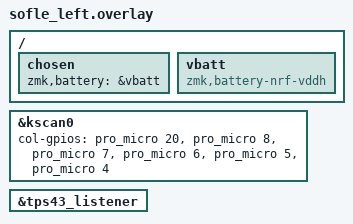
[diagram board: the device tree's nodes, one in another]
/*
 * Copyright (c) 2020 Ryan Cross
 *
 * SPDX-License-Identifier: MIT
 */
#include "sofle.dtsi"

&kscan0 {
    col-gpios
       = <&pro_micro 20 GPIO_ACTIVE_HIGH>
        , <&pro_micro 8 GPIO_ACTIVE_HIGH>
        , <&pro_micro 7 GPIO_ACTIVE_HIGH>
        , <&pro_micro 6 GPIO_ACTIVE_HIGH>
        , <&pro_micro 5 GPIO_ACTIVE_HIGH>
        , <&pro_micro 4 GPIO_ACTIVE_HIGH>
        ;
};

/ {
    chosen {
        zmk,battery = &vbatt;
    };

    vbatt: vbatt {
        compatible = "zmk,battery-nrf-vddh";
    };
};

&tps43_listener {
    status = "okay";
};
```

Es idéntico a tu original porque el dtsi ya tiene todo lo del OLED. No hay que cambiar nada en el overlay, solo asegúrate de añadir esto en `sofle_left.conf`:
```
CONFIG_ZMK_SPLIT_BLE_CENTRAL_PERIPHERALS=1
